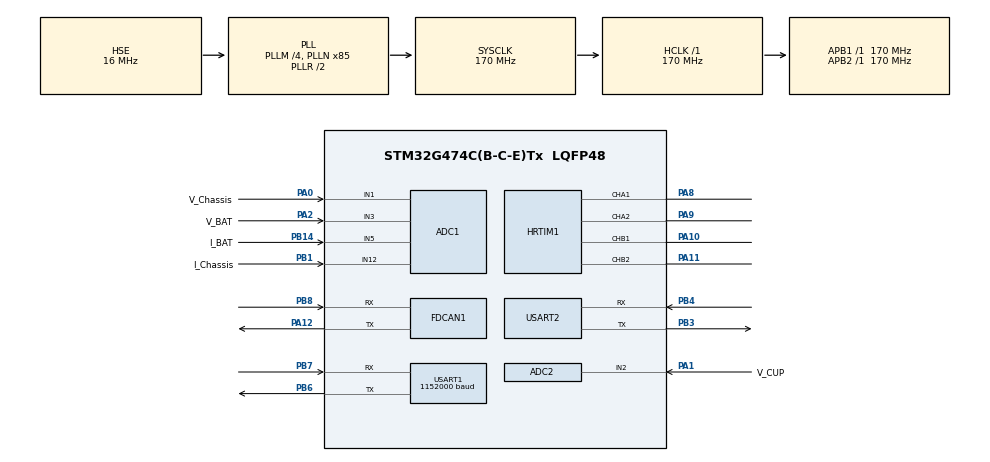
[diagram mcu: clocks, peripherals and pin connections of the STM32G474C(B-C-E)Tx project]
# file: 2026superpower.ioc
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ADC1.Channel-0\#ChannelRegularConversion=ADC_CHANNEL_1
ADC1.Channel-1\#ChannelRegularConversion=ADC_CHANNEL_3
ADC1.Channel-2\#ChannelRegularConversion=ADC_CHANNEL_5
ADC1.Channel-3\#ChannelRegularConversion=ADC_CHANNEL_12
ADC1.DMAContinuousRequests=ENABLE
ADC1.ExternalTrigConv=ADC_EXTERNALTRIG_HRTIM_TRG1
ADC1.NbrOfConversion=4
ADC1.NbrOfConversionFlag=1
ADC1.OffsetNumber-0\#ChannelRegularConversion=ADC_OFFSET_NONE
ADC1.OffsetNumber-1\#ChannelRegularConversion=ADC_OFFSET_NONE
ADC1.OffsetNumber-2\#ChannelRegularConversion=ADC_OFFSET_NONE
ADC1.OffsetNumber-3\#ChannelRegularConversion=ADC_OFFSET_NONE
ADC1.Rank-0\#ChannelRegularConversion=1
ADC1.Rank-1\#ChannelRegularConversion=2
ADC1.Rank-2\#ChannelRegularConversion=3
ADC1.Rank-3\#ChannelRegularConversion=4
ADC1.SamplingTime-0\#ChannelRegularConversion=ADC_SAMPLETIME_2CYCLES_5
ADC1.SamplingTime-1\#ChannelRegularConversion=ADC_SAMPLETIME_2CYCLES_5
ADC1.SamplingTime-2\#ChannelRegularConversion=ADC_SAMPLETIME_2CYCLES_5
ADC1.SamplingTime-3\#ChannelRegularConversion=ADC_SAMPLETIME_2CYCLES_5
ADC1.master=1
ADC2.Channel-0\#ChannelRegularConversion=ADC_CHANNEL_2
ADC2.DMAContinuousRequests=ENABLE
ADC2.ExternalTrigConv=ADC_EXTERNALTRIG_HRTIM_TRG3
ADC2.NbrOfConversionFlag=1
ADC2.OffsetNumber-0\#ChannelRegularConversion=ADC_OFFSET_NONE
ADC2.Rank-0\#ChannelRegularConversion=1
ADC2.SamplingTime-0\#ChannelRegularConversion=ADC_SAMPLETIME_2CYCLES_5
Dma.ADC1.0.Direction=DMA_PERIPH_TO_MEMORY
Dma.ADC1.0.EventEnable=DISABLE
Dma.ADC1.0.Instance=DMA1_Channel1
Dma.ADC1.0.MemDataAlignment=DMA_MDATAALIGN_HALFWORD
Dma.ADC1.0.MemInc=DMA_MINC_ENABLE
Dma.ADC1.0.Mode=DMA_CIRCULAR
Dma.ADC1.0.PeriphDataAlignment=DMA_PDATAALIGN_HALFWORD
Dma.ADC1.0.PeriphInc=DMA_PINC_DISABLE
Dma.ADC1.0.Polarity=HAL_DMAMUX_REQ_GEN_RISING
Dma.ADC1.0.Priority=DMA_PRIORITY_LOW
Dma.ADC1.0.RequestNumber=1
Dma.ADC1.0.SignalID=NONE
Dma.ADC1.0.SyncEnable=DISABLE
Dma.ADC1.0.SyncPolarity=HAL_DMAMUX_SYNC_NO_EVENT
Dma.ADC1.0.SyncRequestNumber=1
Dma.ADC1.0.SyncSignalID=NONE
Dma.ADC2.1.Direction=DMA_PERIPH_TO_MEMORY
Dma.ADC2.1.EventEnable=DISABLE
Dma.ADC2.1.Instance=DMA1_Channel2
Dma.ADC2.1.MemDataAlignment=DMA_MDATAALIGN_HALFWORD
Dma.ADC2.1.MemInc=DMA_MINC_ENABLE
Dma.ADC2.1.Mode=DMA_CIRCULAR
Dma.ADC2.1.PeriphDataAlignment=DMA_PDATAALIGN_HALFWORD
Dma.ADC2.1.PeriphInc=DMA_PINC_DISABLE
Dma.ADC2.1.Polarity=HAL_DMAMUX_REQ_GEN_RISING
Dma.ADC2.1.Priority=DMA_PRIORITY_LOW
Dma.ADC2.1.RequestNumber=1
Dma.ADC2.1.SignalID=NONE
Dma.ADC2.1.SyncEnable=DISABLE
Dma.ADC2.1.SyncPolarity=HAL_DMAMUX_SYNC_NO_EVENT
Dma.ADC2.1.SyncRequestNumber=1
Dma.ADC2.1.SyncSignalID=NONE
Dma.Request0=ADC1
Dma.Request1=ADC2
Dma.Request2=USART1_RX
Dma.Request3=USART1_TX
Dma.Request4=USART2_RX
Dma.Request5=USART2_TX
Dma.USART1_RX.2.Direction=DMA_PERIPH_TO_MEMORY
Dma.USART1_RX.2.EventEnable=DISABLE
Dma.USART1_RX.2.Instance=DMA1_Channel3
Dma.USART1_RX.2.MemDataAlignment=DMA_MDATAALIGN_BYTE
Dma.USART1_RX.2.MemInc=DMA_MINC_ENABLE
Dma.USART1_RX.2.Mode=DMA_NORMAL
Dma.USART1_RX.2.PeriphDataAlignment=DMA_PDATAALIGN_BYTE
Dma.USART1_RX.2.PeriphInc=DMA_PINC_DISABLE
Dma.USART1_RX.2.Polarity=HAL_DMAMUX_REQ_GEN_RISING
Dma.USART1_RX.2.Priority=DMA_PRIORITY_LOW
Dma.USART1_RX.2.RequestNumber=1
Dma.USART1_RX.2.SignalID=NONE
Dma.USART1_RX.2.SyncEnable=DISABLE
Dma.USART1_RX.2.SyncPolarity=HAL_DMAMUX_SYNC_NO_EVENT
Dma.USART1_RX.2.SyncRequestNumber=1
Dma.USART1_RX.2.SyncSignalID=NONE
Dma.USART1_TX.3.Direction=DMA_MEMORY_TO_PERIPH
Dma.USART1_TX.3.EventEnable=DISABLE
Dma.USART1_TX.3.Instance=DMA1_Channel4
Dma.USART1_TX.3.MemDataAlignment=DMA_MDATAALIGN_BYTE
Dma.USART1_TX.3.MemInc=DMA_MINC_ENABLE
Dma.USART1_TX.3.Mode=DMA_NORMAL
Dma.USART1_TX.3.PeriphDataAlignment=DMA_PDATAALIGN_BYTE
Dma.USART1_TX.3.PeriphInc=DMA_PINC_DISABLE
Dma.USART1_TX.3.Polarity=HAL_DMAMUX_REQ_GEN_RISING
Dma.USART1_TX.3.Priority=DMA_PRIORITY_LOW
Dma.USART1_TX.3.RequestNumber=1
Dma.USART1_TX.3.SignalID=NONE
Dma.USART1_TX.3.SyncEnable=DISABLE
Dma.USART1_TX.3.SyncPolarity=HAL_DMAMUX_SYNC_NO_EVENT
Dma.USART1_TX.3.SyncRequestNumber=1
Dma.USART1_TX.3.SyncSignalID=NONE
Dma.USART2_RX.4.Direction=DMA_PERIPH_TO_MEMORY
Dma.USART2_RX.4.EventEnable=DISABLE
Dma.USART2_RX.4.Instance=DMA1_Channel5
Dma.USART2_RX.4.MemDataAlignment=DMA_MDATAALIGN_BYTE
Dma.USART2_RX.4.MemInc=DMA_MINC_ENABLE
Dma.USART2_RX.4.Mode=DMA_NORMAL
Dma.USART2_RX.4.PeriphDataAlignment=DMA_PDATAALIGN_BYTE
Dma.USART2_RX.4.PeriphInc=DMA_PINC_DISABLE
Dma.USART2_RX.4.Polarity=HAL_DMAMUX_REQ_GEN_RISING
Dma.USART2_RX.4.Priority=DMA_PRIORITY_LOW
Dma.USART2_RX.4.RequestNumber=1
Dma.USART2_RX.4.SignalID=NONE
Dma.USART2_RX.4.SyncEnable=DISABLE
Dma.USART2_RX.4.SyncPolarity=HAL_DMAMUX_SYNC_NO_EVENT
Dma.USART2_RX.4.SyncRequestNumber=1
Dma.USART2_RX.4.SyncSignalID=NONE
Dma.USART2_TX.5.Direction=DMA_MEMORY_TO_PERIPH
Dma.USART2_TX.5.EventEnable=DISABLE
Dma.USART2_TX.5.Instance=DMA1_Channel6
Dma.USART2_TX.5.MemDataAlignment=DMA_MDATAALIGN_BYTE
Dma.USART2_TX.5.MemInc=DMA_MINC_ENABLE
Dma.USART2_TX.5.Mode=DMA_NORMAL
Dma.USART2_TX.5.PeriphDataAlignment=DMA_PDATAALIGN_BYTE
Dma.USART2_TX.5.PeriphInc=DMA_PINC_DISABLE
Dma.USART2_TX.5.Polarity=HAL_DMAMUX_REQ_GEN_RISING
Dma.USART2_TX.5.Priority=DMA_PRIORITY_LOW
Dma.USART2_TX.5.RequestNumber=1
Dma.USART2_TX.5.SignalID=NONE
Dma.USART2_TX.5.SyncEnable=DISABLE
Dma.USART2_TX.5.SyncPolarity=HAL_DMAMUX_SYNC_NO_EVENT
Dma.USART2_TX.5.SyncRequestNumber=1
Dma.USART2_TX.5.SyncSignalID=NONE
FDCAN1.CalculateBaudRateNominal=1000000
FDCAN1.CalculateTimeBitNominal=1000
FDCAN1.CalculateTimeQuantumNominal=100.0
FDCAN1.ExtFiltersNbr=0
FDCAN1.NominalPrescaler=17
FDCAN1.NominalTimeSeg1=7
FDCAN1.NominalTimeSeg2=2
FDCAN1.StdFiltersNbr=1
HRTIM1.ADCTrigger1_Source1=HRTIM_ADCTRIGGEREVENT13_TIMERA_CMP3
HRTIM1.ADCTrigger3_Source1=HRTIM_ADCTRIGGEREVENT13_TIMERB_CMP3
HRTIM1.ADCTrigger_Id1=HRTIM_ADCTRIGGER_1
HRTIM1.ADCTrigger_Id2=__NULL
HRTIM1.ADCTrigger_Id3=HRTIM_ADCTRIGGER_3
HRTIM1.CompareUnit1-MasterTimer=HRTIM_COMPAREUNIT_1
HRTIM1.CompareUnit1-Output_TA1TA2=HRTIM_COMPAREUNIT_1
HRTIM1.CompareUnit1-Output_TB1TB2=HRTIM_COMPAREUNIT_1
HRTIM1.CompareUnit2-Output_TA1TA2=HRTIM_COMPAREUNIT_2
HRTIM1.CompareUnit2-Output_TB1TB2=HRTIM_COMPAREUNIT_2
HRTIM1.CompareUnit3-Output_TA1TA2=HRTIM_COMPAREUNIT_3
HRTIM1.CompareUnit3-Output_TB1TB2=HRTIM_COMPAREUNIT_3
HRTIM1.CompareValue1-MasterTimer=10880
HRTIM1.CompareValue1-Output_TA1TA2=10880-5440
HRTIM1.CompareValue1-Output_TB1TB2=10880-5440
HRTIM1.CompareValue2-Output_TA1TA2=10880+5440
HRTIM1.CompareValue2-Output_TB1TB2=10880+5440
HRTIM1.CompareValue3-Output_TA1TA2=10880
HRTIM1.CompareValue3-Output_TB1TB2=10880
HRTIM1.Configuration_TA=Waveform
HRTIM1.DeadTimeInsertion-Output_TA1TA2=HRTIM_TIMDEADTIMEINSERTION_ENABLED
HRTIM1.DeadTimeInsertion-Output_TB1TB2=HRTIM_TIMDEADTIMEINSERTION_ENABLED
HRTIM1.FallingLock-Output_TA1TA2=HRTIM_TIMDEADTIME_FALLINGLOCK_READONLY
HRTIM1.FallingLock-Output_TB1TB2=HRTIM_TIMDEADTIME_FALLINGLOCK_READONLY
HRTIM1.FallingSignLock-Output_TA1TA2=HRTIM_TIMDEADTIME_FALLINGSIGNLOCK_READONLY
HRTIM1.FallingSignLock-Output_TB1TB2=HRTIM_TIMDEADTIME_FALLINGSIGNLOCK_READONLY
HRTIM1.FallingValue-Output_TA1TA2=15
HRTIM1.FallingValue-Output_TB1TB2=15
HRTIM1.GreaterCMP1_TA=HRTIM_TIMERGTCMP1_EQUAL
HRTIM1.GreaterCMP1_TB=HRTIM_TIMERGTCMP1_EQUAL
HRTIM1.GreaterCMP3_TA=HRTIM_TIMERGTCMP3_EQUAL
HRTIM1.GreaterCMP3_TB=HRTIM_TIMERGTCMP3_EQUAL
HRTIM1.InterruptRequests1-Output_TB1TB2=HRTIM_TIM_IT_REP
HRTIM1.InterruptRequests1_Master=HRTIM_MASTER_IT_MREP
HRTIM1.NumberADCTriggerSource1=1
HRTIM1.NumberADCTriggerSource3=1
HRTIM1.NumberInterruptRequests-Output_TB1TB2=1
HRTIM1.NumberInterruptRequests_Master-MasterTimer=1
HRTIM1.NumberResetSource1-Output_TA1TA2=1
HRTIM1.NumberResetSource1-Output_TB1TB2=1
HRTIM1.NumberResetTrigger-Output_TA1TA2=1
HRTIM1.NumberResetTrigger-Output_TB1TB2=1
HRTIM1.NumberSetSource1-Output_TA1TA2=1
HRTIM1.NumberSetSource1-Output_TB1TB2=1
HRTIM1.NumberUpdateTrigger-Output_TA1TA2=0
HRTIM1.NumberUpdateTrigger-Output_TB1TB2=0
HRTIM1.ORingUpdateSource_ADCTrigger1=HRTIM_ADCTRIGGERUPDATE_MASTER
HRTIM1.Periode_MASTER=21760
HRTIM1.Periode_TA=21760
HRTIM1.Periode_TB=21760
HRTIM1.PreloadEnable-Output_TA1TA2=HRTIM_PRELOAD_ENABLED
HRTIM1.PreloadEnable-Output_TB1TB2=HRTIM_PRELOAD_ENABLED
HRTIM1.PrescalerDead-Output_TA1TA2=HRTIM_TIMDEADTIME_PRESCALERRATIO_DIV1
HRTIM1.PrescalerDead-Output_TB1TB2=HRTIM_TIMDEADTIME_PRESCALERRATIO_DIV1
HRTIM1.RepetitionCounter-MasterTimer=249
HRTIM1.RepetitionCounter-Output_TA1TA2=24
HRTIM1.RepetitionCounter-Output_TB1TB2=249
HRTIM1.RepetitionUpdate-Output_TB1TB2=HRTIM_UPDATEONREPETITION_DISABLED
HRTIM1.ResetOutput1_Source1-Output_TA1TA2=HRTIM_OUTPUTRESET_TIMCMP2
HRTIM1.ResetOutput1_Source1-Output_TB1TB2=HRTIM_OUTPUTRESET_TIMCMP2
HRTIM1.ResetTrigger1-Output_TA1TA2=HRTIM_TIMRESETTRIGGER_MASTER_PER
HRTIM1.ResetTrigger1-Output_TB1TB2=HRTIM_TIMRESETTRIGGER_MASTER_CMP1
HRTIM1.ResetUpdate-Output_TA1TA2=HRTIM_TIMUPDATEONRESET_ENABLED
HRTIM1.ResetUpdate-Output_TB1TB2=HRTIM_TIMUPDATEONRESET_ENABLED
HRTIM1.RisingLock-Output_TA1TA2=HRTIM_TIMDEADTIME_RISINGLOCK_READONLY
HRTIM1.RisingLock-Output_TB1TB2=HRTIM_TIMDEADTIME_RISINGLOCK_READONLY
HRTIM1.RisingSignLock-Output_TA1TA2=HRTIM_TIMDEADTIME_RISINGSIGNLOCK_READONLY
HRTIM1.RisingSignLock-Output_TB1TB2=HRTIM_TIMDEADTIME_RISINGSIGNLOCK_READONLY
HRTIM1.RisingValue-Output_TA1TA2=15
HRTIM1.RisingValue-Output_TB1TB2=15
HRTIM1.SetOutput1_Source1-Output_TA1TA2=HRTIM_OUTPUTSET_TIMCMP1
HRTIM1.SetOutput1_Source1-Output_TB1TB2=HRTIM_OUTPUTSET_TIMCMP1
Mcu.Family=STM32G4
Mcu.Name=STM32G474C(B-C-E)Tx
Mcu.Package=LQFP48
NVIC.DMA1_Channel1_IRQn=true\:0\:0\:true\:false\:true\:false\:true\:true
NVIC.DMA1_Channel2_IRQn=true\:1\:0\:true\:false\:true\:false\:true\:true
NVIC.DMA1_Channel3_IRQn=true\:3\:0\:true\:false\:true\:false\:true\:true
NVIC.DMA1_Channel4_IRQn=true\:3\:0\:true\:false\:true\:false\:true\:true
NVIC.DMA1_Channel5_IRQn=true\:3\:0\:true\:false\:true\:false\:true\:true
NVIC.DMA1_Channel6_IRQn=true\:3\:0\:true\:false\:true\:false\:true\:true
NVIC.FDCAN1_IT0_IRQn=true\:3\:0\:true\:false\:true\:true\:true\:true
NVIC.FDCAN1_IT1_IRQn=true\:3\:0\:true\:false\:true\:true\:true\:true
NVIC.HRTIM1_Master_IRQn=true\:1\:0\:true\:false\:true\:true\:true\:true
NVIC.PriorityGroup=NVIC_PRIORITYGROUP_4
NVIC.USART1_IRQn=true\:3\:0\:true\:false\:true\:true\:true\:true
NVIC.USART2_IRQn=true\:0\:0\:false\:false\:true\:true\:true\:true
PA0.GPIO_Label=V_Chassis
PA0.Mode=IN1-Single-Ended
PA0.Signal=ADC1_IN1
PA1.GPIO_Label=V_CUP
PA1.Mode=IN2-Single-Ended
PA1.Signal=ADC2_IN2
PA10.Mode=Output_TB1TB2
PA10.Signal=HRTIM1_CHB1
PA11.Mode=Output_TB1TB2
PA11.Signal=HRTIM1_CHB2
PA12.Mode=FDCAN_Activate
PA12.Signal=FDCAN1_TX
PA2.GPIO_Label=V_BAT
PA2.Mode=IN3-Single-Ended
PA2.Signal=ADC1_IN3
PA8.Mode=Output_TA1TA2
PA8.Signal=HRTIM1_CHA1
PA9.Mode=Output_TA1TA2
PA9.Signal=HRTIM1_CHA2
PB1.GPIO_Label=I_Chassis
PB1.Mode=IN12-Single-Ended
PB1.Signal=ADC1_IN12
PB14.GPIO_Label=I_BAT
PB14.Mode=IN5-Single-Ended
PB14.Signal=ADC1_IN5
PB3.Mode=Asynchronous
PB3.Signal=USART2_TX
PB4.Mode=Asynchronous
PB4.Signal=USART2_RX
PB6.Mode=Asynchronous
PB6.Signal=USART1_TX
PB7.Mode=Asynchronous
PB7.Signal=USART1_RX
PB8-BOOT0.Mode=FDCAN_Activate
PB8-BOOT0.Signal=FDCAN1_RX
PF0-OSC_IN.Mode=HSE-External-Oscillator
PF0-OSC_IN.Signal=RCC_OSC_IN
PF1-OSC_OUT.Mode=HSE-External-Oscillator
PF1-OSC_OUT.Signal=RCC_OSC_OUT
ProjectManager.HeapSize=0x200
ProjectManager.StackSize=0x400
ProjectManager.TargetToolchain=MDK-ARM V5.32
RCC.ADC12Freq_Value=170000000
RCC.ADC345Freq_Value=170000000
RCC.AHBFreq_Value=170000000
RCC.APB1Freq_Value=170000000
RCC.APB1TimFreq_Value=170000000
RCC.APB2Freq_Value=170000000
RCC.APB2TimFreq_Value=170000000
RCC.CortexFreq_Value=170000000
RCC.EXTERNAL_CLOCK_VALUE=12288000
RCC.HCLKFreq_Value=170000000
RCC.HSE_VALUE=16000000
RCC.HSI48_VALUE=48000000
RCC.HSI_VALUE=16000000
RCC.LSE_VALUE=32768
RCC.PLLM=RCC_PLLM_DIV4
RCC.PLLN=85
RCC.PLLSourceVirtual=RCC_PLLSOURCE_HSE
RCC.SYSCLKFreq_VALUE=170000000
RCC.SYSCLKSource=RCC_SYSCLKSOURCE_PLLCLK
RCC.USBFreq_Value=170000000
RCC.VCOOutputFreq_Value=340000000
USART1.BaudRate=1152000
USART1.VirtualMode-Asynchronous=VM_ASYNC
USART2.VirtualMode-Asynchronous=VM_ASYNC
VP_HRTIM1_VS_hrtimMasterTimerNoOutput.Mode=MasterTimer
VP_SYS_VS_DBSignals.Mode=DisableDeadBatterySignals
board=custom

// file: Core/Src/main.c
/* USER CODE BEGIN Header */
/**
  ******************************************************************************
  * @file           : main.c
  * @brief          : Main program body
  ******************************************************************************
  * @attention
  *
  * Copyright (c) 2026 STMicroelectronics.
  * All rights reserved.
  *
  * This software is licensed under terms that can be found in the LICENSE file
  * in the root directory of this software component.
  * If no LICENSE file comes with this software, it is provided AS-IS.
  *
  ******************************************************************************
  */
/* USER CODE END Header */
#include "main.h"
#include "adc.h"
#include "dma.h"
#include "fdcan.h"
#include "hrtim.h"
#include "usart.h"
#include "gpio.h"

/* USER CODE BEGIN Includes */
#include "power_ctrl_task.h"
/* USER CODE END Includes */

void SystemClock_Config(void);

int main(void)
{

  /* MCU Configuration--------------------------------------------------------*/

  /* Reset of all peripherals, Initializes the Flash interface and the Systick. */
  HAL_Init();

  /* Configure the system clock */
  SystemClock_Config();

  /* Initialize all configured peripherals */
  MX_GPIO_Init();
  MX_DMA_Init();
  MX_HRTIM1_Init();
  MX_ADC1_Init();
  MX_ADC2_Init();
  MX_USART1_UART_Init();
  MX_FDCAN1_Init();
  MX_USART2_UART_Init();
  /* USER CODE BEGIN 2 */

    /** @brief 准备 DMA/通信后一次启动 Master/A/B；不直接开启输出。 */
    SuperPower_Init();
  /* USER CODE END 2 */

  /* Infinite loop */
  while (1)
  {

  }
}

void SystemClock_Config(void)
{
  RCC_OscInitTypeDef RCC_OscInitStruct = {0};
  RCC_ClkInitTypeDef RCC_ClkInitStruct = {0};

  /** Configure the main internal regulator output voltage
  */
  HAL_PWREx_ControlVoltageScaling(PWR_REGULATOR_VOLTAGE_SCALE1_BOOST);

  /** Initializes the RCC Oscillators according to the specified parameters
  * in the RCC_OscInitTypeDef structure.
  */
  RCC_OscInitStruct.OscillatorType = RCC_OSCILLATORTYPE_HSE;
  RCC_OscInitStruct.HSEState = RCC_HSE_ON;
  RCC_OscInitStruct.PLL.PLLState = RCC_PLL_ON;
  RCC_OscInitStruct.PLL.PLLSource = RCC_PLLSOURCE_HSE;
  RCC_OscInitStruct.PLL.PLLM = RCC_PLLM_DIV4;
  RCC_OscInitStruct.PLL.PLLN = 85;
  RCC_OscInitStruct.PLL.PLLP = RCC_PLLP_DIV2;
  RCC_OscInitStruct.PLL.PLLQ = RCC_PLLQ_DIV2;
  RCC_OscInitStruct.PLL.PLLR = RCC_PLLR_DIV2;
  if (HAL_RCC_OscConfig(&RCC_OscInitStruct) != HAL_OK)
  {
    Error_Handler();
  }

  /** Initializes the CPU, AHB and APB buses clocks
  */
  RCC_ClkInitStruct.ClockType = RCC_CLOCKTYPE_HCLK|RCC_CLOCKTYPE_SYSCLK
                              |RCC_CLOCKTYPE_PCLK1|RCC_CLOCKTYPE_PCLK2;
  RCC_ClkInitStruct.SYSCLKSource = RCC_SYSCLKSOURCE_PLLCLK;
  RCC_ClkInitStruct.AHBCLKDivider = RCC_SYSCLK_DIV1;
  RCC_ClkInitStruct.APB1CLKDivider = RCC_HCLK_DIV1;
  RCC_ClkInitStruct.APB2CLKDivider = RCC_HCLK_DIV1;

  if (HAL_RCC_ClockConfig(&RCC_ClkInitStruct, FLASH_LATENCY_4) != HAL_OK)
  {
    Error_Handler();
  }
}

void Error_Handler(void)
{
  __disable_irq();
  while (1)
  {
  }
}
